# STM32F205 register map
File version: 1.2
CPU: CM3 r1p1, little endian, no MPU, no FPU, 4 interrupt priority bits
Registers are 32-bit, read-write, reset 0x0 unless marked. A register's access mark holds for its fields unless they carry their own. Offsets are from the block's base; [hi:lo] are bit positions.

## UART4 — Universal synchronous asynchronous receiver transmitter
Base 0x40004C00
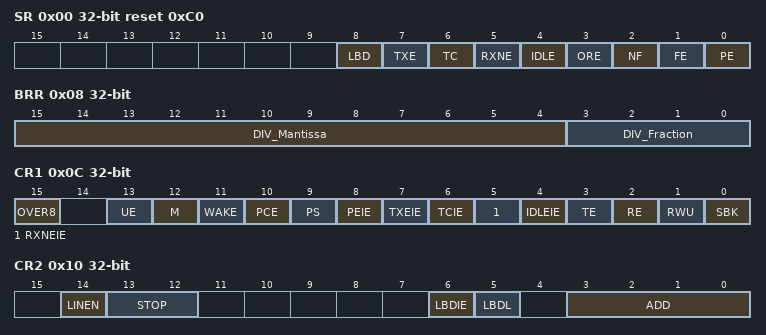
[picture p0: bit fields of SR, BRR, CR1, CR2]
0x00 SR access per field reset 0xC0 — Status register
  [8] LBD rw — LIN break detection flag
  [7] TXE ro — Transmit data register empty
  [6] TC rw — Transmission complete
  [5] RXNE rw — Read data register not empty
  [4] IDLE ro — IDLE line detected
  [3] ORE ro — Overrun error
  [2] NF ro — Noise detected flag
  [1] FE ro — Framing error
  [0] PE ro — Parity error
0x04 DR — Data register
  [8:0] DR — Data value
0x08 BRR — Baud rate register
  [15:4] DIV_Mantissa — mantissa of USARTDIV
  [3:0] DIV_Fraction — fraction of USARTDIV
0x0C CR1 — Control register 1
  [15] OVER8 — Oversampling mode
  [13] UE — USART enable
  [12] M — Word length
  [11] WAKE — Wakeup method
  [10] PCE — Parity control enable
  [9] PS — Parity selection
  [8] PEIE — PE interrupt enable
  [7] TXEIE — TXE interrupt enable
  [6] TCIE — Transmission complete interrupt enable
  [5] RXNEIE — RXNE interrupt enable
  [4] IDLEIE — IDLE interrupt enable
  [3] TE — Transmitter enable
  [2] RE — Receiver enable
  [1] RWU — Receiver wakeup
  [0] SBK — Send break
0x10 CR2 — Control register 2
  [14] LINEN — LIN mode enable
  [13:12] STOP — STOP bits
  [6] LBDIE — LIN break detection interrupt enable
  [5] LBDL — lin break detection length
  [3:0] ADD — Address of the USART node
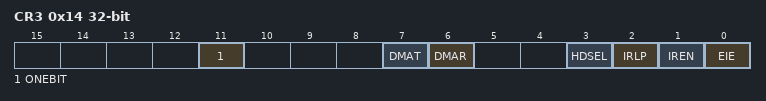
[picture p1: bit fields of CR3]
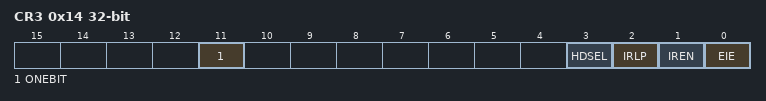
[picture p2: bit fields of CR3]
0x14 CR3 — Control register 3
  [11] ONEBIT — One sample bit method enable
  [7] DMAT — DMA enable transmitter
  [6] DMAR — DMA enable receiver
  [3] HDSEL — Half-duplex selection
  [2] IRLP — IrDA low-power
  [1] IREN — IrDA mode enable
  [0] EIE — Error interrupt enable

## UART5 — Universal synchronous asynchronous receiver transmitter
Base 0x40005000
Registers as UART4; these are added or differ:
0x14 CR3 — Control register 3
  [11] ONEBIT — One sample bit method enable
  [3] HDSEL — Half-duplex selection
  [2] IRLP — IrDA low-power
  [1] IREN — IrDA mode enable
  [0] EIE — Error interrupt enable

## USART6 — Universal synchronous asynchronous receiver transmitter
Base 0x40011400
Same registers: USART2 0x40004400, USART3 0x40004800, USART1 0x40011000
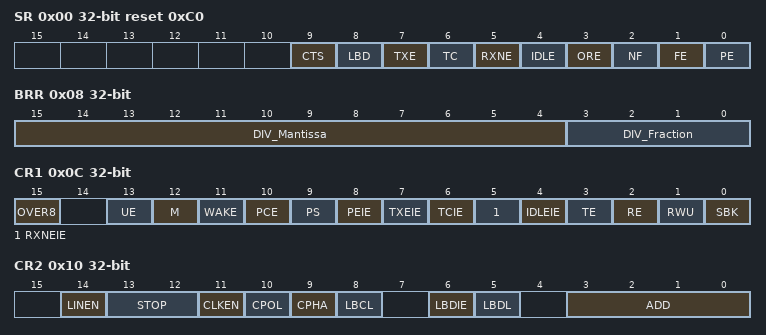
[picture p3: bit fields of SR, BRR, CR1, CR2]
0x00 SR access per field reset 0xC0 — Status register
  [9] CTS rw — CTS flag
  [8] LBD rw — LIN break detection flag
  [7] TXE ro — Transmit data register empty
  [6] TC rw — Transmission complete
  [5] RXNE rw — Read data register not empty
  [4] IDLE ro — IDLE line detected
  [3] ORE ro — Overrun error
  [2] NF ro — Noise detected flag
  [1] FE ro — Framing error
  [0] PE ro — Parity error
0x04 DR — Data register
  [8:0] DR — Data value
0x08 BRR — Baud rate register
  [15:4] DIV_Mantissa — mantissa of USARTDIV
  [3:0] DIV_Fraction — fraction of USARTDIV
0x0C CR1 — Control register 1
  [15] OVER8 — Oversampling mode
  [13] UE — USART enable
  [12] M — Word length
  [11] WAKE — Wakeup method
  [10] PCE — Parity control enable
  [9] PS — Parity selection
  [8] PEIE — PE interrupt enable
  [7] TXEIE — TXE interrupt enable
  [6] TCIE — Transmission complete interrupt enable
  [5] RXNEIE — RXNE interrupt enable
  [4] IDLEIE — IDLE interrupt enable
  [3] TE — Transmitter enable
  [2] RE — Receiver enable
  [1] RWU — Receiver wakeup
  [0] SBK — Send break
0x10 CR2 — Control register 2
  [14] LINEN — LIN mode enable
  [13:12] STOP — STOP bits
  [11] CLKEN — Clock enable
  [10] CPOL — Clock polarity
  [9] CPHA — Clock phase
  [8] LBCL — Last bit clock pulse
  [6] LBDIE — LIN break detection interrupt enable
  [5] LBDL — lin break detection length
  [3:0] ADD — Address of the USART node
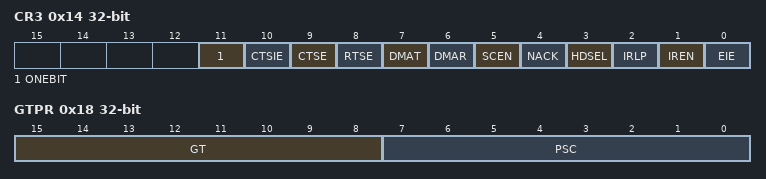
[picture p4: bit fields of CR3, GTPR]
0x14 CR3 — Control register 3
  [11] ONEBIT — One sample bit method enable
  [10] CTSIE — CTS interrupt enable
  [9] CTSE — CTS enable
  [8] RTSE — RTS enable
  [7] DMAT — DMA enable transmitter
  [6] DMAR — DMA enable receiver
  [5] SCEN — Smartcard mode enable
  [4] NACK — Smartcard NACK enable
  [3] HDSEL — Half-duplex selection
  [2] IRLP — IrDA low-power
  [1] IREN — IrDA mode enable
  [0] EIE — Error interrupt enable
0x18 GTPR — Guard time and prescaler register
  [15:8] GT — Guard time value
  [7:0] PSC — Prescaler value

## WWDG — Window watchdog
Base 0x40002C00
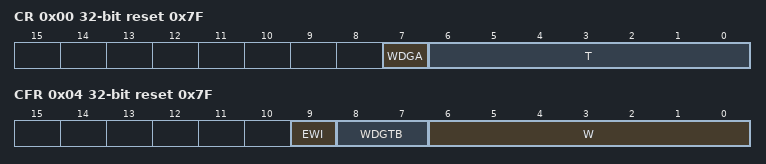
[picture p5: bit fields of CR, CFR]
0x00 CR reset 0x7F — Control register
  [7] WDGA — Activation bit
  [6:0] T — 7-bit counter (MSB to LSB)
0x04 CFR reset 0x7F — Configuration register
  [9] EWI — Early wakeup interrupt
  [8:7] WDGTB — Timer base
  [6:0] W — 7-bit window value
0x08 SR — Status register
  [0] EWIF — Early wakeup interrupt flag
